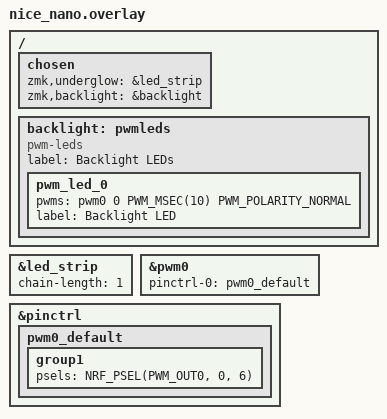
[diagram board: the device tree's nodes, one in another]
#include <dt-bindings/led/led.h>

/ {
    chosen {
        zmk,underglow = &led_strip;
        zmk,backlight = &backlight;
    };

    backlight: pwmleds {
        compatible = "pwm-leds";
        label = "Backlight LEDs";
        pwm_led_0: pwm_led_0 {
            pwms = <&pwm0 0 PWM_MSEC(10) PWM_POLARITY_NORMAL>;
            label = "Backlight LED";
        };
    };
};

&led_strip {
    chain-length = <1>;
};

&pwm0 {
    status = "okay";
    pinctrl-0 = <&pwm0_default>;
    pinctrl-names = "default";
};

&pinctrl {
    pwm0_default: pwm0_default {
        group1 {
            psels = <NRF_PSEL(PWM_OUT0, 0, 6)>; /* 백라이트 핀 번호 - 실제 핀으로 수정 필요 */
        };
    };
};
